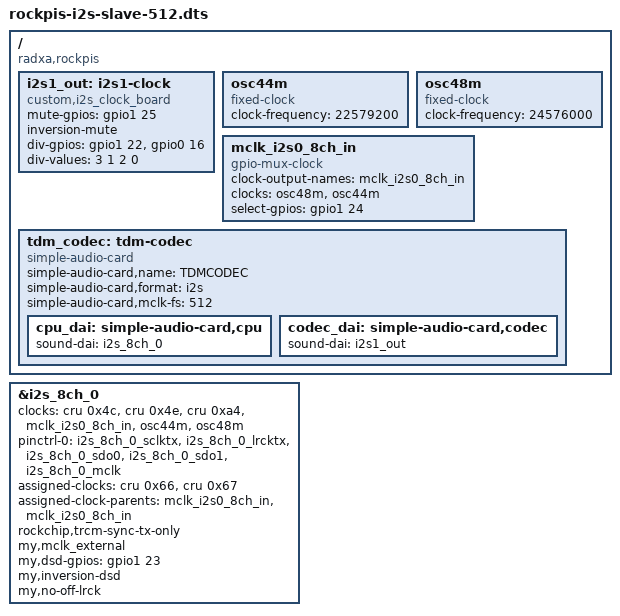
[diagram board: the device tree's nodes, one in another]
/dts-v1/;
/plugin/;

/ {
    compatible = "radxa,rockpis", "rockchip,rk3308";
	
 	fragment@0 {
 		target-path = "/";
 		__overlay__ {
            i2s1_out: i2s1-clock {
                #sound-dai-cells = <0>;
                compatible = "custom,i2s_clock_board";
                // GPIO1_D1
                mute-gpios = <&gpio1 25 0>;
                inversion-mute;
                // 0 bit GPIO1_C6, 1 bit GPIO0_C0
                div-gpios = <&gpio1 22 0>, <&gpio0 16 0>;
                div-values = /bits/ 8 <3 1 2 0>;
                status = "okay";
            };
 		};
 	};

	fragment@1 {
        target-path = "/";
        __overlay__ {
            osc44m: osc44m {
                compatible = "fixed-clock";
                #clock-cells = <0>;
                clock-frequency = <22579200>;
            };

            osc48m: osc48m {
                compatible = "fixed-clock";
                #clock-cells = <0>;
                clock-frequency = <24576000>;
            };

            mclk_i2s0_8ch_in: mclk_i2s0_8ch_in {
                compatible = "gpio-mux-clock";
                #clock-cells = <0>;
                clock-output-names = "mclk_i2s0_8ch_in";
                clocks = <&osc48m>, <&osc44m>;
				// GPIO1_D0
                select-gpios = <&gpio1 24 0>;
            };
        };
    };

    fragment@3 {
        target = <&i2s_8ch_0>;
        __overlay__ {
            #sound-dai-cells = <0>;
			//compatible = "rockchip,rk3308-i2s-tdm";
            //clocks = <&cru SCLK_I2S0_8CH_TX>, <&cru SCLK_I2S0_8CH_RX>, <&cru HCLK_I2S0_8CH>,
            //    <&mclk_i2s0_8ch_in>, <&clk_44>, <&clk_48>;
            clocks = <&cru 0x4c>, <&cru 0x4e>, <&cru 0xa4>,
                <&mclk_i2s0_8ch_in>, <&osc44m>, <&osc48m>;
            clock-names = 	"mclk_tx", "mclk_rx", "hclk",
                "mclk_ext", "clk_44", "clk_48";
            //pinctrl-names = "default";
            pinctrl-0 = <&i2s_8ch_0_sclktx
                    &i2s_8ch_0_lrcktx
                    &i2s_8ch_0_sdo0
                    &i2s_8ch_0_sdo1
                    &i2s_8ch_0_mclk>;
            status = "okay";
            //assigned-clocks = <&cru SCLK_I2S0_8CH_TX_MUX>, <&cru SCLK_I2S0_8CH_RX_MUX>;
            assigned-clocks = <&cru 0x66>, <&cru 0x67>;
            assigned-clock-parents = <&mclk_i2s0_8ch_in>, <&mclk_i2s0_8ch_in>;
			rockchip,trcm-sync-tx-only;
            my,mclk_external;
			// GPIO1_C7
            my,dsd-gpios = <&gpio1 23 0>;
			my,inversion-dsd;
			my,no-off-lrck;
        };
    };

    fragment@4 {
        target-path = "/";
        __overlay__ {
			tdm_codec: tdm-codec {
				compatible = "simple-audio-card";
				simple-audio-card,name = "TDMCODEC";
				simple-audio-card,format = "i2s";
				simple-audio-card,mclk-fs = <512>;
				status = "okay";

				cpu_dai: simple-audio-card,cpu {
					sound-dai = <&i2s_8ch_0>;
				};
						
				codec_dai: simple-audio-card,codec {
					sound-dai = <&i2s1_out>;
				};
			};
        };
    };
};
